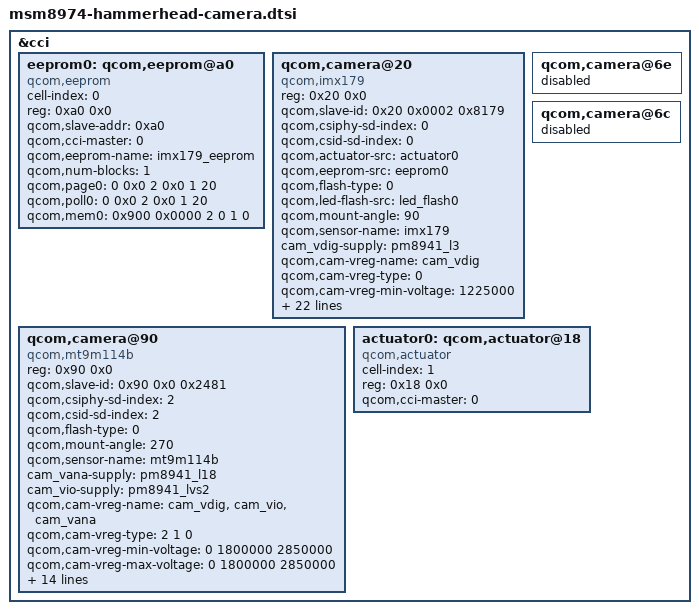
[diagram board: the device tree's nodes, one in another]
/*
 * Copyright (c) 2012, The Linux Foundation. All rights reserved.
 *
 * This program is free software; you can redistribute it and/or modify
 * it under the terms of the GNU General Public License version 2 and
 * only version 2 as published by the Free Software Foundation.
 *
 * This program is distributed in the hope that it will be useful,
 * but WITHOUT ANY WARRANTY; without even the implied warranty of
 * MERCHANTABILITY or FITNESS FOR A PARTICULAR PURPOSE.  See the
 * GNU General Public License for more details.
 */

&cci {
	eeprom0: qcom,eeprom@a0 {
		cell-index = <0>;
		reg = <0xa0 0x0>;
		compatible = "qcom,eeprom";
		qcom,slave-addr = <0xa0>;
		qcom,cci-master = <0>;
		qcom,eeprom-name = "imx179_eeprom";
		qcom,num-blocks = <1>;
		qcom,page0 = <0 0x0 2 0x0 1 20>;
		qcom,poll0 = <0 0x0 2 0x0 1 20>;
		qcom,mem0 = <0x900 0x0000 2 0 1 0>;
	};

	qcom,camera@20 {
		status = "ok";
		compatible = "qcom,imx179";
		reg = <0x20 0x0>;
		qcom,slave-id = <0x20 0x0002 0x8179>;
		qcom,csiphy-sd-index = <0>;
		qcom,csid-sd-index = <0>;
		qcom,actuator-src = <&actuator0>;
		qcom,eeprom-src = <&eeprom0>;
		qcom,flash-type = <0>;
		qcom,led-flash-src = <&led_flash0>;
		qcom,mount-angle = <90>;
		qcom,sensor-name = "imx179";
		cam_vdig-supply = <&pm8941_l3>;
		qcom,cam-vreg-name = "cam_vdig";
		qcom,cam-vreg-type = <0>;
		qcom,cam-vreg-min-voltage = <1225000>;
		qcom,cam-vreg-max-voltage = <1225000>;
		qcom,cam-vreg-op-mode = <1225000>;
		qcom,gpio-no-mux = <0>;
		gpios = <&msmgpio 15 0>,  // MCLK
			<&msmgpio 4 0>,   // MAIN_CAM_RESET
			<&msmgpio 16 0>,  // 13M_VANA_EN
			<&msmgpio 96 0>,  // 13M_VIO_EN
			<&msmgpio 57 0>,  // 13M_VCM_EN
			<&msmgpio 145 0>, // OIS_LDO_EN
			<&msmgpio 29 0>;  // OIS_RESET
		qcom,gpio-reset = <1>;
		qcom,gpio-vana = <2>;
		qcom,gpio-vio = <3>;
		qcom,gpio-vcm = <4>;
		qcom,gpio-ois-ldo = <5>;
		qcom,gpio-ois-reset = <6>;
		qcom,gpio-req-tbl-num = <0 1 2 3 4 5 6>;
		qcom,gpio-req-tbl-flags = <0 0 0 0 0 0 0>;
		qcom,gpio-req-tbl-label = "CAMIF_MCLK",
			"CAM_RESET1",
			"MAIN_VANA_EN",
			"MAIN_VIO_EN",
			"MAIN_VCM_EN",
			"OIS_LDO_EN",
			"OIS_RESET";
		qcom,csi-lane-assign = <0x4320>;
		qcom,csi-lane-mask = <0x1F>;
		qcom,sensor-position = <0>;
		qcom,sensor-mode = <0>;
		qcom,cci-master = <0>;
	};

	qcom,camera@6e {
		status = "disabled";
	};

	qcom,camera@6c {
		status = "disabled";
	};

	qcom,camera@90 {
		status = "ok";
		compatible = "qcom,mt9m114b";
		reg = <0x90 0x0>;
		qcom,slave-id = <0x90 0x0 0x2481>;
		qcom,csiphy-sd-index = <2>;
		qcom,csid-sd-index = <2>;
		qcom,flash-type = <0>;
		qcom,mount-angle = <270>;
		qcom,sensor-name = "mt9m114b";
		cam_vana-supply = <&pm8941_l18>;
		cam_vio-supply = <&pm8941_lvs2>;
		qcom,cam-vreg-name = "cam_vdig", "cam_vio", "cam_vana";
		qcom,cam-vreg-type = <2 1 0>;
		qcom,cam-vreg-min-voltage = <0 1800000 2850000>;
		qcom,cam-vreg-max-voltage = <0 1800000 2850000>;
		qcom,cam-vreg-op-mode = <0 1800000 2850000>;
		qcom,gpio-no-mux = <0>;
		gpios = <&msmgpio 17 0>, //VT_CAM_MCLK
			<&msmgpio 18 0>, //VT_CAM_RESET
			<&msmgpio 30 0>; //VT_LDO_EN
		qcom,gpio-reset = <1>;
		qcom,gpio-vdig = <2>;
		qcom,gpio-req-tbl-num = <0 1 2>;
		qcom,gpio-req-tbl-flags = <0 0 0>;
		qcom,gpio-req-tbl-label = "CAMIF_MCLK2",
					     "CAM_RESET2",
					     "VT_LDO_EN";
		qcom,csi-lane-assign = <0x4320>;
		qcom,csi-lane-mask = <0x3>;
		qcom,sensor-position = <1>;
		qcom,sensor-mode = <1>;
		qcom,cci-master = <1>;
	};

	actuator0: qcom,actuator@18 {
		cell-index = <1>;
		reg = <0x18 0x0>;
		compatible = "qcom,actuator";
		qcom,cci-master = <0>;
	};
};
